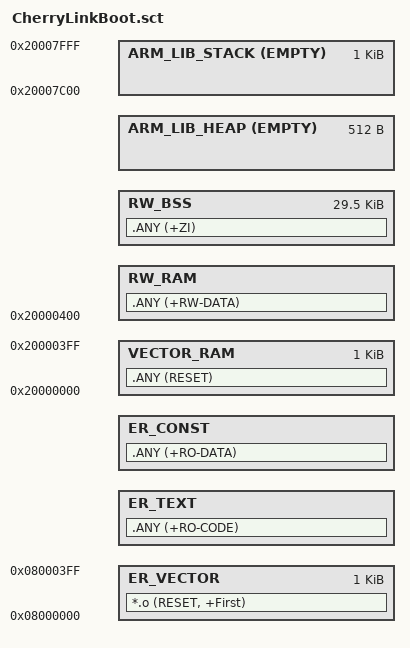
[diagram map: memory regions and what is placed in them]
#! armclang --target=arm-arm-none-eabi -mcpu=cortex-m3 -E -xc
;#! armcc -E
; *********************************************************************
; *** Scatter-Loading Description File generated by SecondHandCoder ***
; *********************************************************************

#define stack_size                      0x00000400
#define heap_size                       0x00000200
#define boot_size						0x00002000

#define m_flash_start					0x08000000
#define m_flash_size					0x00020000

#define m_rom_start                     m_flash_start
#define m_rom_size                      boot_size

#define m_vector_size                   0x00000400
#define m_vector_ram_size       		0x00000400

#define m_ram_start                     0x20000000
#define m_ram_size                      0x00008000

LR_IROM m_rom_start m_rom_size
{
	ER_VECTOR m_rom_start m_vector_size
	{
		*.o (RESET, +First)
	}
	ER_TEXT +0
	{
		.ANY (+RO-CODE)
	}
	ER_CONST +0
	{
		.ANY (+RO-DATA)
	}

	VECTOR_RAM m_ram_start m_vector_ram_size
	{
		.ANY (RESET) 
	}    

	RW_RAM m_ram_start+m_vector_ram_size
	{
		.ANY (+RW-DATA)
	}

	RW_BSS +0 m_ram_size-stack_size-heap_size-m_vector_ram_size
	{
		.ANY (+ZI)
	}

	ARM_LIB_HEAP +0 EMPTY heap_size
	{

	}

	ARM_LIB_STACK m_ram_start+m_ram_size EMPTY -stack_size
	{

	}
}
